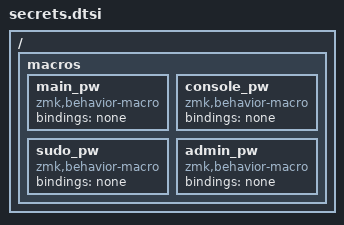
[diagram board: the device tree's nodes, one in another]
/*
 * PLACEHOLDER. This file is in git, so it must never hold real passwords.
 * The build overwrites it with the MACROS_COMBOS_DTSI Actions secret.
 * Same labels as the real macros so every keymap builds without the
 * secret; these all type nothing.
 */
/ {
    macros {
        main_pw: main_pw {
            compatible = "zmk,behavior-macro";
            #binding-cells = <0>;
            bindings = <&none>;
        };
        console_pw: console_pw {
            compatible = "zmk,behavior-macro";
            #binding-cells = <0>;
            bindings = <&none>;
        };
        sudo_pw: sudo_pw {
            compatible = "zmk,behavior-macro";
            #binding-cells = <0>;
            bindings = <&none>;
        };
        admin_pw: admin_pw {
            compatible = "zmk,behavior-macro";
            #binding-cells = <0>;
            bindings = <&none>;
        };
    };
};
